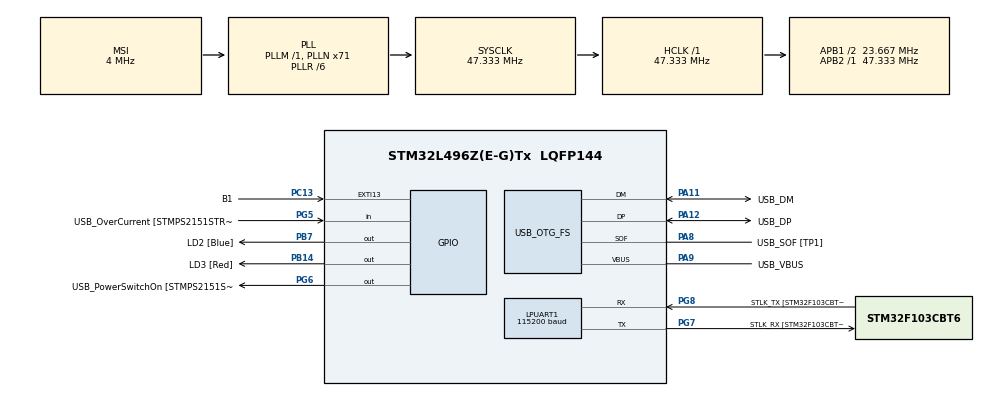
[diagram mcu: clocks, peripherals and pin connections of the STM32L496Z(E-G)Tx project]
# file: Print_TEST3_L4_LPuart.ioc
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LPUART1.BaudRate=115200
LPUART1.WordLength=UART_WORDLENGTH_8B
Mcu.Family=STM32L4
Mcu.Name=STM32L496Z(E-G)Tx
Mcu.Package=LQFP144
NVIC.PriorityGroup=NVIC_PRIORITYGROUP_4
PA10.GPIO_Label=USB_ID
PA10.Signal=USB_OTG_FS_ID
PA11.GPIO_Label=USB_DM
PA11.Mode=Device_Only
PA11.Signal=USB_OTG_FS_DM
PA12.GPIO_Label=USB_DP
PA12.Mode=Device_Only
PA12.Signal=USB_OTG_FS_DP
PA13\ (JTMS/SWDIO).GPIO_Label=TMS
PA13\ (JTMS/SWDIO).Mode=Trace_Asynchronous_SW
PA13\ (JTMS/SWDIO).Signal=SYS_JTMS-SWDIO
PA14\ (JTCK/SWCLK).GPIO_Label=TCK
PA14\ (JTCK/SWCLK).Mode=Trace_Asynchronous_SW
PA14\ (JTCK/SWCLK).Signal=SYS_JTCK-SWCLK
PA8.GPIO_Label=USB_SOF [TP1]
PA8.Mode=Activate_SOF_FS
PA8.Signal=USB_OTG_FS_SOF
PA9.GPIO_Label=USB_VBUS
PA9.Mode=Activate_VBUS
PA9.Signal=USB_OTG_FS_VBUS
PB14.GPIO_Label=LD3 [Red]
PB14.Signal=GPIO_Output
PB3\ (JTDO/TRACESWO).GPIO_Label=SWO
PB3\ (JTDO/TRACESWO).Mode=Trace_Asynchronous_SW
PB3\ (JTDO/TRACESWO).Signal=SYS_JTDO-SWO
PB7.GPIO_Label=LD2 [Blue]
PB7.Signal=GPIO_Output
PC13.GPIO_Label=B1
PC13.Signal=GPXTI13
PC14-OSC32_IN\ (PC14).Mode=LSE-External-Oscillator
PC14-OSC32_IN\ (PC14).Signal=RCC_OSC32_IN
PC15-OSC32_OUT\ (PC15).Mode=LSE-External-Oscillator
PC15-OSC32_OUT\ (PC15).Signal=RCC_OSC32_OUT
PG5.GPIO_Label=USB_OverCurrent [STMPS2151STR_FAULT]
PG5.Signal=GPIO_Input
PG6.GPIO_Label=USB_PowerSwitchOn [STMPS2151STR_EN]
PG6.Signal=GPIO_Output
PG7.GPIO_Label=STLK_RX [STM32F103CBT6_PA3]
PG7.Mode=Asynchronous
PG7.Signal=LPUART1_TX
PG8.GPIO_Label=STLK_TX [STM32F103CBT6_PA2]
PG8.Mode=Asynchronous
PG8.Signal=LPUART1_RX
PH1-OSC_OUT\ (PH1).Signal=RCC_OSC_OUT
ProjectManager.HeapSize=0x200
ProjectManager.StackSize=0x400
ProjectManager.TargetToolchain=STM32CubeIDE
RCC.48MHZClocksFreq_Value=24000000
RCC.ADCFreq_Value=48000000
RCC.AHBFreq_Value=47333333.333333336
RCC.APB1CLKDivider=RCC_HCLK_DIV2
RCC.APB1Freq_Value=23666666.666666668
RCC.APB1TimFreq_Value=47333333.333333336
RCC.APB2Freq_Value=47333333.333333336
RCC.APB2TimFreq_Value=47333333.333333336
RCC.CortexFreq_Value=47333333.333333336
RCC.HCLKFreq_Value=47333333.333333336
RCC.HSE_VALUE=8000000
RCC.HSI48_VALUE=48000000
RCC.HSI_VALUE=16000000
RCC.MSI_VALUE=4000000
RCC.PLLMUL=RCC_PLL_MUL9
RCC.PLLN=71
RCC.PLLR=RCC_PLLR_DIV6
RCC.PLLSAI1N=24
RCC.PRESCALERUSB=RCC_USBCLKSOURCE_PLL_DIV1_5
RCC.SYSCLKFreq_VALUE=47333333.333333336
RCC.SYSCLKSource=RCC_SYSCLKSOURCE_PLLCLK
RCC.SYSCLKSourceVirtual=RCC_SYSCLKSOURCE_PLLCLK
RCC.USBFreq_Value=48000000
RCC.VCOOutputFreq_Value=284000000
USB_OTG_FS.VirtualMode=Device_Only
board=NUCLEO-L496ZG

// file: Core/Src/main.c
/* USER CODE BEGIN Header */
/**
  ******************************************************************************
  * @file           : main.c
  * @brief          : Main program body
  ******************************************************************************
  * @attention
  *
  * Copyright (c) 2023 STMicroelectronics.
  * All rights reserved.
  *
  * This software is licensed under terms that can be found in the LICENSE file
  * in the root directory of this software component.
  * If no LICENSE file comes with this software, it is provided AS-IS.
  *
  ******************************************************************************
  */
/* USER CODE END Header */
#include "main.h"

/* USER CODE BEGIN Includes */
#include "tools.h"
/* USER CODE END Includes */

UART_HandleTypeDef hlpuart1;

PCD_HandleTypeDef hpcd_USB_OTG_FS;

void SystemClock_Config(void);
static void MX_GPIO_Init(void);
static void MX_LPUART1_UART_Init(void);
static void MX_USB_OTG_FS_PCD_Init(void);

int main(void)
{
  /* USER CODE BEGIN 1 */
	int pes = 4574;
  /* USER CODE END 1 */

  /* MCU Configuration--------------------------------------------------------*/

  /* Reset of all peripherals, Initializes the Flash interface and the Systick. */
  HAL_Init();

  /* Configure the system clock */
  SystemClock_Config();

  /* Initialize all configured peripherals */
  MX_GPIO_Init();
  MX_LPUART1_UART_Init();
  MX_USB_OTG_FS_PCD_Init();

  /* Infinite loop */
  /* USER CODE BEGIN WHILE */
  while (1)
  {
	  myPrint("smooth \n\r");
	  myPrint("%d a very big hairy ass \n\r", pes);
	  pes++;
    /* USER CODE END WHILE */

  }
}

void SystemClock_Config(void)
{
  RCC_OscInitTypeDef RCC_OscInitStruct = {0};
  RCC_ClkInitTypeDef RCC_ClkInitStruct = {0};

  /** Configure the main internal regulator output voltage
  */
  if (HAL_PWREx_ControlVoltageScaling(PWR_REGULATOR_VOLTAGE_SCALE1) != HAL_OK)
  {
    Error_Handler();
  }

  /** Configure LSE Drive Capability
  */
  HAL_PWR_EnableBkUpAccess();
  __HAL_RCC_LSEDRIVE_CONFIG(RCC_LSEDRIVE_LOW);

  /** Initializes the RCC Oscillators according to the specified parameters
  * in the RCC_OscInitTypeDef structure.
  */
  RCC_OscInitStruct.OscillatorType = RCC_OSCILLATORTYPE_LSE|RCC_OSCILLATORTYPE_MSI;
  RCC_OscInitStruct.LSEState = RCC_LSE_ON;
  RCC_OscInitStruct.MSIState = RCC_MSI_ON;
  RCC_OscInitStruct.MSICalibrationValue = 0;
  RCC_OscInitStruct.MSIClockRange = RCC_MSIRANGE_6;
  RCC_OscInitStruct.PLL.PLLState = RCC_PLL_ON;
  RCC_OscInitStruct.PLL.PLLSource = RCC_PLLSOURCE_MSI;
  RCC_OscInitStruct.PLL.PLLM = 1;
  RCC_OscInitStruct.PLL.PLLN = 71;
  RCC_OscInitStruct.PLL.PLLP = RCC_PLLP_DIV2;
  RCC_OscInitStruct.PLL.PLLQ = RCC_PLLQ_DIV2;
  RCC_OscInitStruct.PLL.PLLR = RCC_PLLR_DIV6;
  if (HAL_RCC_OscConfig(&RCC_OscInitStruct) != HAL_OK)
  {
    Error_Handler();
  }

  /** Initializes the CPU, AHB and APB buses clocks
  */
  RCC_ClkInitStruct.ClockType = RCC_CLOCKTYPE_HCLK|RCC_CLOCKTYPE_SYSCLK
                              |RCC_CLOCKTYPE_PCLK1|RCC_CLOCKTYPE_PCLK2;
  RCC_ClkInitStruct.SYSCLKSource = RCC_SYSCLKSOURCE_PLLCLK;
  RCC_ClkInitStruct.AHBCLKDivider = RCC_SYSCLK_DIV1;
  RCC_ClkInitStruct.APB1CLKDivider = RCC_HCLK_DIV2;
  RCC_ClkInitStruct.APB2CLKDivider = RCC_HCLK_DIV1;

  if (HAL_RCC_ClockConfig(&RCC_ClkInitStruct, FLASH_LATENCY_2) != HAL_OK)
  {
    Error_Handler();
  }

  /** Enable MSI Auto calibration
  */
  HAL_RCCEx_EnableMSIPLLMode();
}

static void MX_LPUART1_UART_Init(void)
{

  hlpuart1.Instance = LPUART1;
  hlpuart1.Init.BaudRate = 115200;
  hlpuart1.Init.WordLength = UART_WORDLENGTH_8B;
  hlpuart1.Init.StopBits = UART_STOPBITS_1;
  hlpuart1.Init.Parity = UART_PARITY_NONE;
  hlpuart1.Init.Mode = UART_MODE_TX_RX;
  hlpuart1.Init.HwFlowCtl = UART_HWCONTROL_NONE;
  hlpuart1.Init.OneBitSampling = UART_ONE_BIT_SAMPLE_DISABLE;
  hlpuart1.AdvancedInit.AdvFeatureInit = UART_ADVFEATURE_NO_INIT;
  if (HAL_UART_Init(&hlpuart1) != HAL_OK)
  {
    Error_Handler();
  }

}

static void MX_USB_OTG_FS_PCD_Init(void)
{

  hpcd_USB_OTG_FS.Instance = USB_OTG_FS;
  hpcd_USB_OTG_FS.Init.dev_endpoints = 6;
  hpcd_USB_OTG_FS.Init.speed = PCD_SPEED_FULL;
  hpcd_USB_OTG_FS.Init.phy_itface = PCD_PHY_EMBEDDED;
  hpcd_USB_OTG_FS.Init.Sof_enable = ENABLE;
  hpcd_USB_OTG_FS.Init.low_power_enable = DISABLE;
  hpcd_USB_OTG_FS.Init.lpm_enable = DISABLE;
  hpcd_USB_OTG_FS.Init.battery_charging_enable = ENABLE;
  hpcd_USB_OTG_FS.Init.use_dedicated_ep1 = DISABLE;
  hpcd_USB_OTG_FS.Init.vbus_sensing_enable = ENABLE;
  if (HAL_PCD_Init(&hpcd_USB_OTG_FS) != HAL_OK)
  {
    Error_Handler();
  }

}

static void MX_GPIO_Init(void)
{
  GPIO_InitTypeDef GPIO_InitStruct = {0};

  /* GPIO Ports Clock Enable */
  __HAL_RCC_GPIOC_CLK_ENABLE();
  __HAL_RCC_GPIOH_CLK_ENABLE();
  __HAL_RCC_GPIOB_CLK_ENABLE();
  __HAL_RCC_GPIOG_CLK_ENABLE();
  HAL_PWREx_EnableVddIO2();
  __HAL_RCC_GPIOA_CLK_ENABLE();

  /*Configure GPIO pin Output Level */
  HAL_GPIO_WritePin(GPIOB, LD3_Pin|LD2_Pin, GPIO_PIN_RESET);

  /*Configure GPIO pin Output Level */
  HAL_GPIO_WritePin(USB_PowerSwitchOn_GPIO_Port, USB_PowerSwitchOn_Pin, GPIO_PIN_RESET);

  /*Configure GPIO pin : B1_Pin */
  GPIO_InitStruct.Pin = B1_Pin;
  GPIO_InitStruct.Mode = GPIO_MODE_IT_RISING;
  GPIO_InitStruct.Pull = GPIO_NOPULL;
  HAL_GPIO_Init(B1_GPIO_Port, &GPIO_InitStruct);

  /*Configure GPIO pins : LD3_Pin LD2_Pin */
  GPIO_InitStruct.Pin = LD3_Pin|LD2_Pin;
  GPIO_InitStruct.Mode = GPIO_MODE_OUTPUT_PP;
  GPIO_InitStruct.Pull = GPIO_NOPULL;
  GPIO_InitStruct.Speed = GPIO_SPEED_FREQ_LOW;
  HAL_GPIO_Init(GPIOB, &GPIO_InitStruct);

  /*Configure GPIO pin : USB_OverCurrent_Pin */
  GPIO_InitStruct.Pin = USB_OverCurrent_Pin;
  GPIO_InitStruct.Mode = GPIO_MODE_INPUT;
  GPIO_InitStruct.Pull = GPIO_NOPULL;
  HAL_GPIO_Init(USB_OverCurrent_GPIO_Port, &GPIO_InitStruct);

  /*Configure GPIO pin : USB_PowerSwitchOn_Pin */
  GPIO_InitStruct.Pin = USB_PowerSwitchOn_Pin;
  GPIO_InitStruct.Mode = GPIO_MODE_OUTPUT_PP;
  GPIO_InitStruct.Pull = GPIO_NOPULL;
  GPIO_InitStruct.Speed = GPIO_SPEED_FREQ_LOW;
  HAL_GPIO_Init(USB_PowerSwitchOn_GPIO_Port, &GPIO_InitStruct);

}

void Error_Handler(void)
{
  __disable_irq();
  while (1)
  {
  }
}
